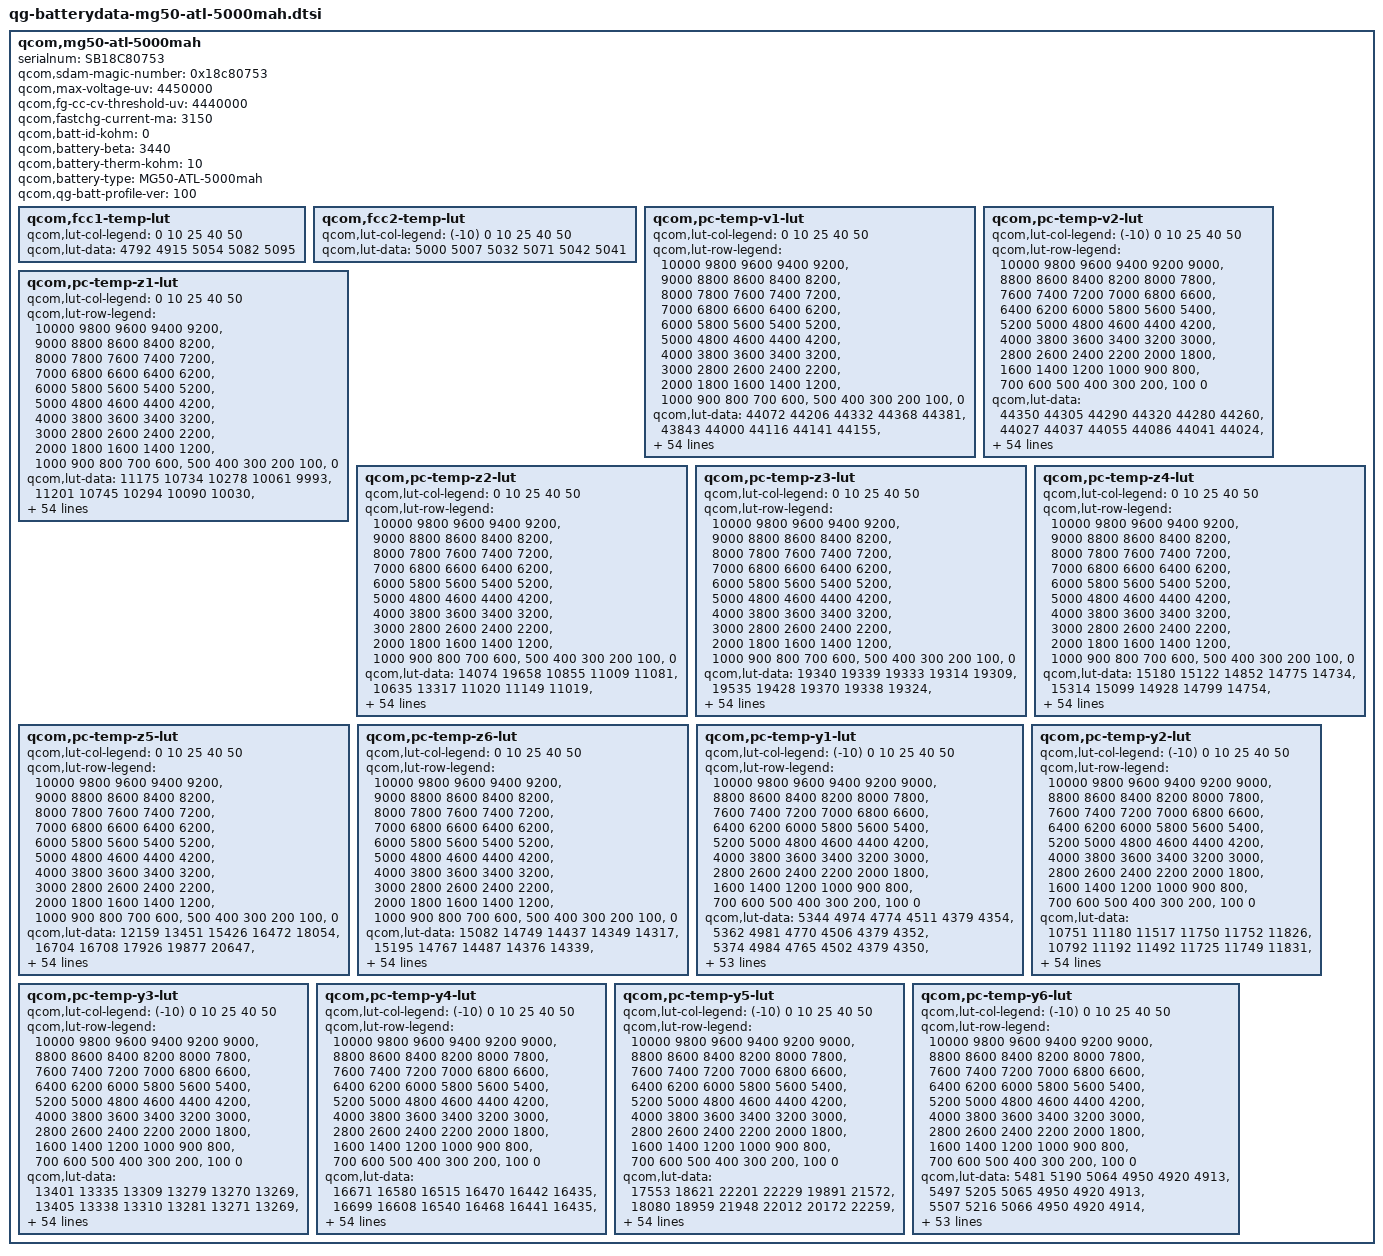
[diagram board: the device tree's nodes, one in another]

qcom,mg50-atl-5000mah {
    /* 4674913_Lenovo_Odessa_5000mAH_PM7150_averaged_MasterSlave_Jun29th2020 */
    serialnum = "SB18C80753";
    qcom,sdam-magic-number = <0x18c80753>;
    qcom,max-voltage-uv = <4450000>;
    qcom,fg-cc-cv-threshold-uv = <4440000>;
    qcom,fastchg-current-ma = <3150>;
    qcom,batt-id-kohm = <0>;
    qcom,battery-beta = <3440>;
    qcom,battery-therm-kohm = <10>;
    qcom,battery-type = "MG50-ATL-5000mah";
    qcom,qg-batt-profile-ver = <100>;

	qcom,fcc1-temp-lut {
		qcom,lut-col-legend = <0 10 25 40 50>;
		qcom,lut-data = <4792 4915 5054 5082 5095>;
	};

	qcom,fcc2-temp-lut {
		qcom,lut-col-legend = <(-10) 0 10 25 40 50>;
		qcom,lut-data = <5000 5007 5032 5071 5042 5041>;
	};

	qcom,pc-temp-v1-lut {
		qcom,lut-col-legend = <0 10 25 40 50>;
		qcom,lut-row-legend = <10000 9800 9600 9400 9200>,
			<9000 8800 8600 8400 8200>,
			<8000 7800 7600 7400 7200>,
			<7000 6800 6600 6400 6200>,
			<6000 5800 5600 5400 5200>,
			<5000 4800 4600 4400 4200>,
			<4000 3800 3600 3400 3200>,
			<3000 2800 2600 2400 2200>,
			<2000 1800 1600 1400 1200>,
			<1000 900 800 700 600>,
			<500 400 300 200 100>,
			<0>;
		qcom,lut-data = <44072 44206 44332 44368 44381>,
			<43843 44000 44116 44141 44155>,
			<43634 43792 43920 43941 43952>,
			<43423 43587 43721 43746 43757>,
			<43199 43375 43511 43540 43554>,
			<42969 43151 43294 43328 43345>,
			<42738 42916 43067 43106 43127>,
			<42504 42679 42830 42875 42897>,
			<42273 42442 42590 42638 42661>,
			<42047 42205 42348 42398 42422>,
			<41824 41973 42105 42156 42181>,
			<41606 41746 41868 41918 41943>,
			<41391 41523 41636 41684 41707>,
			<41184 41305 41408 41454 41476>,
			<40986 41092 41186 41230 41251>,
			<40799 40889 40969 41011 41033>,
			<40612 40694 40761 40800 40821>,
			<40421 40504 40560 40596 40616>,
			<40228 40327 40368 40399 40417>,
			<40029 40147 40192 40217 40232>,
			<39813 39921 40013 40039 40054>,
			<39597 39625 39783 39822 39840>,
			<39399 39374 39504 39553 39571>,
			<39213 39221 39279 39316 39328>,
			<39069 39102 39123 39143 39157>,
			<38967 38986 38992 38997 39013>,
			<38884 38874 38867 38868 38882>,
			<38800 38770 38752 38755 38763>,
			<38717 38675 38648 38650 38653>,
			<38640 38586 38551 38549 38551>,
			<38570 38507 38464 38456 38457>,
			<38504 38434 38385 38370 38368>,
			<38445 38369 38313 38292 38286>,
			<38390 38311 38249 38219 38207>,
			<38340 38260 38195 38153 38133>,
			<38297 38212 38143 38089 38060>,
			<38261 38172 38092 38023 37981>,
			<38214 38128 38042 37956 37895>,
			<38134 38056 37973 37876 37803>,
			<38027 37949 37871 37775 37701>,
			<37909 37830 37753 37660 37589>,
			<37771 37697 37625 37531 37457>,
			<37615 37548 37482 37389 37309>,
			<37436 37369 37312 37227 37146>,
			<37300 37221 37171 37096 37025>,
			<37227 37131 37088 37026 36959>,
			<37189 37108 37063 37004 36939>,
			<37156 37084 37048 36986 36923>,
			<37123 37057 37021 36959 36894>,
			<37046 36976 36900 36820 36726>,
			<36751 36648 36548 36469 36367>,
			<36283 36178 36066 35992 35890>,
			<35689 35573 35442 35379 35273>,
			<34884 34743 34592 34543 34431>,
			<33624 33444 33248 33241 33115>,
			<30000 30000 30000 30000 30000>;
	};

	qcom,pc-temp-v2-lut {
		qcom,lut-col-legend = <(-10) 0 10 25 40 50>;
		qcom,lut-row-legend = <10000 9800 9600 9400 9200 9000>,
			<8800 8600 8400 8200 8000 7800>,
			<7600 7400 7200 7000 6800 6600>,
			<6400 6200 6000 5800 5600 5400>,
			<5200 5000 4800 4600 4400 4200>,
			<4000 3800 3600 3400 3200 3000>,
			<2800 2600 2400 2200 2000 1800>,
			<1600 1400 1200 1000 900 800>,
			<700 600 500 400 300 200>,
			<100 0>;
		qcom,lut-data = <44350 44305 44290 44320 44280 44260>,
			<44027 44037 44055 44086 44041 44024>,
			<43729 43784 43828 43859 43810 43795>,
			<43462 43552 43612 43643 43591 43578>,
			<43225 43339 43405 43436 43382 43370>,
			<42991 43124 43193 43223 43168 43158>,
			<42748 42894 42965 42992 42939 42930>,
			<42505 42657 42729 42754 42702 42696>,
			<42261 42420 42492 42514 42465 42461>,
			<42016 42178 42251 42270 42224 42222>,
			<41770 41939 42012 42029 41986 41985>,
			<41512 41702 41776 41790 41750 41749>,
			<41263 41470 41543 41555 41518 41516>,
			<41075 41247 41315 41323 41289 41288>,
			<40937 41030 41091 41096 41066 41065>,
			<40776 40821 40873 40877 40849 40849>,
			<40519 40627 40663 40667 40641 40639>,
			<40209 40432 40458 40462 40439 40436>,
			<39931 40208 40259 40267 40248 40245>,
			<39676 39952 40065 40078 40068 40065>,
			<39435 39695 39851 39867 39867 39866>,
			<39205 39441 39581 39613 39620 39622>,
			<38990 39199 39309 39365 39370 39375>,
			<38799 38999 39101 39156 39164 39172>,
			<38621 38828 38928 38969 38982 38993>,
			<38470 38676 38775 38813 38828 38840>,
			<38348 38541 38638 38683 38700 38711>,
			<38248 38418 38515 38567 38587 38597>,
			<38172 38299 38402 38458 38480 38488>,
			<38112 38183 38298 38356 38380 38387>,
			<38057 38087 38203 38264 38289 38294>,
			<38004 38013 38115 38180 38207 38210>,
			<37953 37953 38035 38101 38129 38131>,
			<37900 37903 37960 38026 38054 38050>,
			<37846 37863 37889 37952 37980 37970>,
			<37789 37823 37825 37871 37892 37873>,
			<37727 37783 37771 37783 37775 37740>,
			<37659 37741 37716 37692 37656 37606>,
			<37580 37682 37644 37599 37555 37500>,
			<37486 37603 37558 37500 37460 37405>,
			<37380 37499 37458 37400 37358 37302>,
			<37259 37350 37336 37295 37248 37189>,
			<37123 37180 37198 37168 37120 37059>,
			<36976 37012 37040 37026 36972 36909>,
			<36848 36865 36920 36914 36879 36826>,
			<36758 36785 36858 36888 36853 36799>,
			<36717 36755 36833 36867 36835 36782>,
			<36673 36718 36803 36841 36817 36766>,
			<36613 36662 36747 36791 36775 36703>,
			<36496 36550 36599 36596 36581 36454>,
			<36235 36276 36230 36161 36171 36023>,
			<35798 35804 35689 35599 35639 35473>,
			<35199 35168 34986 34865 34949 34756>,
			<34382 34327 33999 33813 33986 33767>,
			<33143 33052 32505 32418 32692 32474>,
			<30382 30452 30248 29025 29492 29251>;
	};

	qcom,pc-temp-z1-lut {
		qcom,lut-col-legend = <0 10 25 40 50>;
		qcom,lut-row-legend = <10000 9800 9600 9400 9200>,
			<9000 8800 8600 8400 8200>,
			<8000 7800 7600 7400 7200>,
			<7000 6800 6600 6400 6200>,
			<6000 5800 5600 5400 5200>,
			<5000 4800 4600 4400 4200>,
			<4000 3800 3600 3400 3200>,
			<3000 2800 2600 2400 2200>,
			<2000 1800 1600 1400 1200>,
			<1000 900 800 700 600>,
			<500 400 300 200 100>,
			<0>;
		qcom,lut-data = <11175 10734 10278 10061 9993>,
			<11201 10745 10294 10090 10030>,
			<11218 10745 10295 10092 10036>,
			<11226 10736 10295 10093 10038>,
			<11211 10724 10289 10092 10041>,
			<11175 10714 10279 10091 10043>,
			<11149 10701 10273 10090 10044>,
			<11130 10691 10269 10090 10043>,
			<11118 10677 10265 10089 10042>,
			<11116 10664 10261 10088 10042>,
			<11108 10661 10258 10086 10042>,
			<11098 10661 10254 10085 10042>,
			<11079 10660 10251 10084 10042>,
			<11057 10654 10249 10083 10042>,
			<11049 10648 10249 10083 10042>,
			<11042 10648 10248 10084 10043>,
			<11039 10651 10248 10084 10044>,
			<11040 10652 10249 10085 10044>,
			<11043 10645 10249 10086 10045>,
			<11046 10634 10250 10087 10046>,
			<11043 10634 10252 10088 10047>,
			<11037 10640 10254 10089 10049>,
			<11035 10644 10256 10090 10050>,
			<11035 10644 10258 10091 10051>,
			<11037 10645 10261 10093 10052>,
			<11040 10645 10264 10095 10054>,
			<11042 10648 10268 10098 10056>,
			<11042 10650 10272 10100 10058>,
			<11039 10652 10276 10103 10059>,
			<11036 10656 10281 10105 10061>,
			<11039 10659 10286 10108 10063>,
			<11050 10664 10289 10111 10065>,
			<11055 10668 10291 10114 10067>,
			<11055 10671 10294 10117 10069>,
			<11057 10675 10301 10120 10072>,
			<11062 10678 10309 10123 10074>,
			<11075 10683 10313 10126 10076>,
			<11084 10689 10318 10130 10078>,
			<11083 10697 10322 10133 10080>,
			<11080 10710 10329 10135 10083>,
			<11086 10717 10335 10137 10084>,
			<11114 10715 10341 10140 10086>,
			<11134 10714 10346 10142 10088>,
			<11144 10731 10349 10144 10089>,
			<11148 10738 10354 10147 10090>,
			<11123 10751 10362 10148 10092>,
			<11135 10746 10359 10149 10091>,
			<11128 10728 10362 10149 10092>,
			<11129 10744 10362 10151 10093>,
			<11150 10758 10375 10155 10095>,
			<11159 10760 10379 10158 10098>,
			<11166 10767 10389 10163 10101>,
			<11186 10773 10393 10168 10107>,
			<11205 10788 10404 10176 10115>,
			<11205 10788 10404 10176 10115>,
			<11205 10788 10404 10176 10115>;
	};

	qcom,pc-temp-z2-lut {
		qcom,lut-col-legend = <0 10 25 40 50>;
		qcom,lut-row-legend = <10000 9800 9600 9400 9200>,
			<9000 8800 8600 8400 8200>,
			<8000 7800 7600 7400 7200>,
			<7000 6800 6600 6400 6200>,
			<6000 5800 5600 5400 5200>,
			<5000 4800 4600 4400 4200>,
			<4000 3800 3600 3400 3200>,
			<3000 2800 2600 2400 2200>,
			<2000 1800 1600 1400 1200>,
			<1000 900 800 700 600>,
			<500 400 300 200 100>,
			<0>;
		qcom,lut-data = <14074 19658 10855 11009 11081>,
			<10635 13317 11020 11149 11019>,
			<10632 10817 11021 11138 11021>,
			<10629 10785 11019 11116 11040>,
			<10608 10755 10969 11070 11019>,
			<10569 10722 10884 10985 10952>,
			<10538 10687 10854 10932 10926>,
			<10514 10659 10844 10900 10910>,
			<10497 10634 10838 10878 10887>,
			<10487 10618 10837 10873 10888>,
			<10480 10626 10841 10874 10894>,
			<10478 10658 10848 10880 10901>,
			<10488 10683 10862 10889 10913>,
			<10508 10694 10871 10896 10927>,
			<10531 10702 10874 10891 10938>,
			<10564 10712 10877 10878 10953>,
			<10589 10721 10879 10880 10972>,
			<10598 10731 10882 10911 11018>,
			<10603 10742 10887 10941 11062>,
			<10611 10751 10894 10952 11078>,
			<10629 10752 10907 10965 11089>,
			<10645 10746 10934 11028 11158>,
			<10638 10742 10988 11277 11522>,
			<10608 10743 11030 11437 11782>,
			<10590 10744 11064 11433 11614>,
			<10589 10749 11086 11405 11290>,
			<10589 10776 11076 11321 11100>,
			<10590 10796 11039 11086 10969>,
			<10597 10786 11003 10946 10893>,
			<10607 10766 10952 10923 10859>,
			<10620 10761 10912 10909 10839>,
			<10635 10774 10919 10895 10848>,
			<10650 10790 10952 10878 10898>,
			<10665 10803 10985 10873 10961>,
			<10678 10816 11022 10932 11056>,
			<10686 10822 11053 11018 11158>,
			<10691 10823 11066 11075 11230>,
			<10698 10825 11075 11125 11291>,
			<10712 10838 11094 11190 11308>,
			<10727 10871 11159 11305 11286>,
			<10730 10885 11207 11388 11264>,
			<10724 10868 11190 11378 11268>,
			<10730 10857 11163 11356 11277>,
			<10796 10887 11162 11313 11273>,
			<10719 11073 11202 11245 11250>,
			<10490 11170 11242 11259 11228>,
			<10667 11143 11235 11249 11228>,
			<10873 11129 11163 11257 11311>,
			<10913 11140 11141 11309 11493>,
			<11029 11204 11243 11211 11218>,
			<10707 11289 11173 10995 10981>,
			<10594 11388 11100 10933 10928>,
			<10534 11627 11039 10873 10865>,
			<10232 11587 10962 10792 10789>,
			<10232 11587 10962 10792 10789>,
			<10232 11587 10962 10792 10789>;
	};

	qcom,pc-temp-z3-lut {
		qcom,lut-col-legend = <0 10 25 40 50>;
		qcom,lut-row-legend = <10000 9800 9600 9400 9200>,
			<9000 8800 8600 8400 8200>,
			<8000 7800 7600 7400 7200>,
			<7000 6800 6600 6400 6200>,
			<6000 5800 5600 5400 5200>,
			<5000 4800 4600 4400 4200>,
			<4000 3800 3600 3400 3200>,
			<3000 2800 2600 2400 2200>,
			<2000 1800 1600 1400 1200>,
			<1000 900 800 700 600>,
			<500 400 300 200 100>,
			<0>;
		qcom,lut-data = <19340 19339 19333 19314 19309>,
			<19535 19428 19370 19338 19324>,
			<19573 19471 19385 19347 19332>,
			<19590 19484 19394 19353 19335>,
			<19602 19492 19400 19358 19337>,
			<19609 19496 19403 19362 19340>,
			<19611 19498 19403 19363 19341>,
			<19612 19499 19397 19357 19338>,
			<19612 19497 19392 19350 19334>,
			<19611 19494 19389 19347 19333>,
			<19608 19489 19387 19346 19332>,
			<19604 19480 19383 19344 19331>,
			<19600 19474 19378 19341 19330>,
			<19595 19470 19374 19338 19329>,
			<19589 19468 19372 19335 19326>,
			<19582 19466 19370 19332 19323>,
			<19577 19464 19368 19330 19320>,
			<19573 19462 19366 19328 19318>,
			<19569 19458 19364 19327 19315>,
			<19568 19453 19362 19324 19313>,
			<19580 19455 19361 19322 19311>,
			<19594 19469 19363 19323 19311>,
			<19594 19478 19370 19329 19319>,
			<19588 19469 19373 19339 19329>,
			<19583 19452 19368 19354 19341>,
			<19581 19450 19362 19369 19351>,
			<19578 19464 19368 19369 19353>,
			<19577 19476 19388 19363 19348>,
			<19575 19476 19396 19356 19342>,
			<19574 19474 19393 19351 19336>,
			<19572 19472 19389 19346 19330>,
			<19568 19468 19385 19341 19325>,
			<19566 19465 19380 19336 19321>,
			<19564 19462 19376 19332 19317>,
			<19563 19460 19372 19327 19312>,
			<19561 19459 19370 19324 19308>,
			<19559 19457 19368 19324 19309>,
			<19556 19456 19366 19325 19311>,
			<19552 19453 19366 19327 19314>,
			<19545 19448 19365 19330 19317>,
			<19540 19444 19365 19332 19319>,
			<19536 19441 19363 19332 19319>,
			<19529 19437 19359 19331 19319>,
			<19514 19431 19358 19333 19323>,
			<19387 19406 19350 19330 19321>,
			<19262 19393 19337 19313 19306>,
			<19261 19388 19338 19311 19304>,
			<19260 19388 19332 19308 19300>,
			<19260 19390 19331 19306 19294>,
			<19260 19382 19332 19317 19309>,
			<19261 19375 19339 19325 19314>,
			<19261 19349 19345 19327 19314>,
			<19261 19311 19348 19327 19315>,
			<19263 19304 19346 19329 19318>,
			<19263 19304 19346 19329 19318>,
			<19263 19304 19346 19329 19318>;
	};

	qcom,pc-temp-z4-lut {
		qcom,lut-col-legend = <0 10 25 40 50>;
		qcom,lut-row-legend = <10000 9800 9600 9400 9200>,
			<9000 8800 8600 8400 8200>,
			<8000 7800 7600 7400 7200>,
			<7000 6800 6600 6400 6200>,
			<6000 5800 5600 5400 5200>,
			<5000 4800 4600 4400 4200>,
			<4000 3800 3600 3400 3200>,
			<3000 2800 2600 2400 2200>,
			<2000 1800 1600 1400 1200>,
			<1000 900 800 700 600>,
			<500 400 300 200 100>,
			<0>;
		qcom,lut-data = <15180 15122 14852 14775 14734>,
			<15314 15099 14928 14799 14754>,
			<15233 15061 14880 14778 14744>,
			<15137 14995 14827 14747 14721>,
			<15062 14923 14792 14724 14704>,
			<14991 14872 14763 14703 14686>,
			<14935 14829 14739 14690 14675>,
			<14890 14795 14718 14683 14670>,
			<14853 14767 14703 14677 14666>,
			<14823 14745 14696 14672 14662>,
			<14799 14731 14690 14668 14658>,
			<14779 14721 14686 14664 14655>,
			<14760 14715 14683 14660 14651>,
			<14746 14712 14680 14657 14647>,
			<14738 14710 14675 14653 14644>,
			<14733 14708 14671 14650 14642>,
			<14731 14706 14669 14646 14639>,
			<14736 14705 14667 14642 14635>,
			<14746 14706 14666 14639 14632>,
			<14755 14708 14665 14638 14630>,
			<14761 14717 14664 14638 14628>,
			<14768 14758 14678 14645 14633>,
			<14782 14790 14726 14684 14668>,
			<14806 14797 14750 14708 14695>,
			<14817 14800 14754 14695 14683>,
			<14808 14798 14755 14675 14663>,
			<14791 14771 14745 14667 14655>,
			<14780 14745 14713 14664 14651>,
			<14772 14735 14694 14661 14649>,
			<14766 14729 14689 14658 14647>,
			<14763 14727 14686 14654 14645>,
			<14762 14727 14685 14652 14642>,
			<14761 14727 14684 14651 14639>,
			<14760 14728 14684 14650 14638>,
			<14759 14728 14684 14650 14637>,
			<14757 14728 14685 14651 14637>,
			<14754 14725 14686 14652 14640>,
			<14749 14722 14687 14656 14646>,
			<14743 14719 14688 14657 14648>,
			<14737 14717 14689 14658 14647>,
			<14728 14713 14689 14658 14645>,
			<14714 14701 14684 14657 14645>,
			<14699 14687 14674 14653 14645>,
			<14684 14676 14667 14649 14643>,
			<14742 14654 14655 14641 14635>,
			<14847 14640 14639 14634 14625>,
			<14845 14637 14630 14628 14619>,
			<14843 14631 14626 14618 14612>,
			<14841 14625 14623 14613 14610>,
			<14837 14634 14630 14617 14615>,
			<14839 14648 14631 14620 14619>,
			<14841 14676 14627 14620 14621>,
			<14841 14722 14625 14621 14622>,
			<14843 14731 14628 14621 14621>,
			<14843 14731 14628 14621 14621>,
			<14843 14731 14628 14621 14621>;
	};

	qcom,pc-temp-z5-lut {
		qcom,lut-col-legend = <0 10 25 40 50>;
		qcom,lut-row-legend = <10000 9800 9600 9400 9200>,
			<9000 8800 8600 8400 8200>,
			<8000 7800 7600 7400 7200>,
			<7000 6800 6600 6400 6200>,
			<6000 5800 5600 5400 5200>,
			<5000 4800 4600 4400 4200>,
			<4000 3800 3600 3400 3200>,
			<3000 2800 2600 2400 2200>,
			<2000 1800 1600 1400 1200>,
			<1000 900 800 700 600>,
			<500 400 300 200 100>,
			<0>;
		qcom,lut-data = <12159 13451 15426 16472 18054>,
			<16704 16708 17926 19877 20647>,
			<18288 18834 19164 21162 22388>,
			<19464 20026 20318 22189 23392>,
			<20633 21031 21173 23584 24429>,
			<21662 22253 21911 25185 26014>,
			<22806 23555 22543 25730 27034>,
			<24112 24924 23151 25444 27245>,
			<25479 26535 23750 25130 27437>,
			<26823 28054 24485 25393 28021>,
			<28190 29034 25142 26150 29113>,
			<29763 29744 25208 26669 30305>,
			<31900 30365 24952 26911 31837>,
			<33996 30897 24794 27029 32994>,
			<35287 31431 25273 27141 32951>,
			<36388 32303 26159 27424 32530>,
			<37218 33703 26865 28076 32510>,
			<37375 34448 27505 29688 33995>,
			<37043 33014 28126 30889 35702>,
			<37544 30854 28771 31077 36676>,
			<43479 31960 29346 31167 37449>,
			<50277 40287 29783 31365 37646>,
			<49926 46119 30173 31716 37259>,
			<44182 39772 30165 31935 36574>,
			<40057 28512 25733 31622 34805>,
			<39373 26002 20717 31048 32551>,
			<38941 29687 21789 30679 32274>,
			<39236 34208 26726 30064 32930>,
			<41569 37618 30752 29789 33289>,
			<44252 40789 33311 30663 32632>,
			<46116 43137 35486 31937 31750>,
			<47819 44977 37709 32715 31897>,
			<49046 46259 39916 33596 32931>,
			<50010 46972 41126 34197 33630>,
			<50622 47499 41783 34651 33907>,
			<50576 47624 42113 35164 34186>,
			<50167 47015 41657 35791 34853>,
			<49735 45973 40346 36535 36255>,
			<49221 44592 38995 37073 37580>,
			<48656 42661 37439 37419 38786>,
			<48402 41595 36148 37718 39949>,
			<48274 41249 35289 38165 40887>,
			<48208 41102 34714 38513 41943>,
			<47804 40909 34596 39387 46586>,
			<31426 42089 33066 37216 43900>,
			<12145 43348 32153 26343 27915>,
			<12074 37719 37151 27977 30700>,
			<12029 38889 33456 33798 35395>,
			<12012 42098 33477 37122 32905>,
			<12027 32659 28730 41389 45599>,
			<12103 25844 28701 39604 40548>,
			<12025 20655 30953 38536 36123>,
			<11935 14143 32422 34663 33089>,
			<11885 13609 29058 32801 31621>,
			<11885 13609 29058 32801 31621>,
			<11885 13609 29058 32801 31621>;
	};

	qcom,pc-temp-z6-lut {
		qcom,lut-col-legend = <0 10 25 40 50>;
		qcom,lut-row-legend = <10000 9800 9600 9400 9200>,
			<9000 8800 8600 8400 8200>,
			<8000 7800 7600 7400 7200>,
			<7000 6800 6600 6400 6200>,
			<6000 5800 5600 5400 5200>,
			<5000 4800 4600 4400 4200>,
			<4000 3800 3600 3400 3200>,
			<3000 2800 2600 2400 2200>,
			<2000 1800 1600 1400 1200>,
			<1000 900 800 700 600>,
			<500 400 300 200 100>,
			<0>;
		qcom,lut-data = <15082 14749 14437 14349 14317>,
			<15195 14767 14487 14376 14339>,
			<15147 14769 14474 14371 14338>,
			<15087 14737 14457 14362 14333>,
			<15034 14693 14444 14356 14328>,
			<14981 14662 14431 14350 14323>,
			<14935 14635 14419 14344 14318>,
			<14896 14611 14406 14337 14314>,
			<14862 14591 14396 14331 14311>,
			<14834 14573 14390 14327 14308>,
			<14809 14559 14386 14324 14306>,
			<14788 14548 14381 14321 14304>,
			<14769 14540 14377 14318 14301>,
			<14753 14536 14373 14315 14299>,
			<14742 14532 14369 14311 14296>,
			<14733 14529 14366 14308 14293>,
			<14729 14526 14364 14306 14290>,
			<14729 14524 14362 14303 14287>,
			<14729 14521 14361 14301 14285>,
			<14731 14519 14360 14299 14283>,
			<14738 14523 14359 14298 14281>,
			<14748 14549 14366 14302 14283>,
			<14755 14568 14392 14323 14305>,
			<14763 14566 14403 14338 14321>,
			<14766 14561 14403 14339 14320>,
			<14761 14558 14402 14340 14319>,
			<14754 14555 14401 14339 14317>,
			<14750 14552 14398 14334 14314>,
			<14747 14549 14395 14330 14310>,
			<14745 14546 14392 14326 14306>,
			<14743 14545 14390 14322 14302>,
			<14742 14544 14387 14319 14299>,
			<14742 14543 14385 14316 14295>,
			<14742 14543 14384 14313 14292>,
			<14743 14544 14383 14311 14290>,
			<14744 14545 14383 14310 14288>,
			<14745 14546 14383 14311 14289>,
			<14746 14546 14384 14313 14293>,
			<14747 14547 14385 14315 14296>,
			<14748 14547 14387 14318 14297>,
			<14748 14547 14388 14319 14297>,
			<14748 14544 14385 14319 14298>,
			<14747 14541 14381 14317 14298>,
			<14743 14538 14379 14316 14299>,
			<14715 14524 14371 14312 14296>,
			<14703 14514 14359 14301 14284>,
			<14703 14511 14356 14297 14280>,
			<14703 14510 14352 14291 14274>,
			<14705 14511 14351 14288 14270>,
			<14710 14515 14356 14296 14281>,
			<14715 14521 14362 14302 14286>,
			<14721 14524 14364 14304 14288>,
			<14729 14528 14367 14307 14291>,
			<14740 14536 14371 14310 14294>,
			<14740 14536 14371 14310 14294>,
			<14740 14536 14371 14310 14294>;
	};

	qcom,pc-temp-y1-lut {
		qcom,lut-col-legend = <(-10) 0 10 25 40 50>;
		qcom,lut-row-legend = <10000 9800 9600 9400 9200 9000>,
			<8800 8600 8400 8200 8000 7800>,
			<7600 7400 7200 7000 6800 6600>,
			<6400 6200 6000 5800 5600 5400>,
			<5200 5000 4800 4600 4400 4200>,
			<4000 3800 3600 3400 3200 3000>,
			<2800 2600 2400 2200 2000 1800>,
			<1600 1400 1200 1000 900 800>,
			<700 600 500 400 300 200>,
			<100 0>;
		qcom,lut-data = <5344 4974 4774 4511 4379 4354>,
			<5362 4981 4770 4506 4379 4352>,
			<5374 4984 4765 4502 4379 4350>,
			<5381 4986 4760 4498 4378 4349>,
			<5385 4986 4755 4494 4377 4347>,
			<5385 4986 4750 4490 4376 4346>,
			<5381 4984 4745 4487 4375 4346>,
			<5373 4981 4741 4484 4374 4346>,
			<5372 4981 4739 4482 4373 4345>,
			<5375 4983 4739 4480 4372 4344>,
			<5378 4984 4738 4478 4372 4344>,
			<5380 4983 4735 4476 4371 4343>,
			<5382 4981 4730 4474 4371 4343>,
			<5383 4979 4727 4473 4371 4343>,
			<5385 4977 4725 4472 4370 4343>,
			<5387 4976 4723 4472 4369 4343>,
			<5388 4978 4720 4471 4370 4343>,
			<5388 4981 4717 4471 4371 4344>,
			<5389 4983 4717 4471 4371 4344>,
			<5398 4984 4718 4472 4371 4344>,
			<5406 4986 4720 4473 4371 4345>,
			<5402 4988 4721 4474 4372 4346>,
			<5394 4990 4722 4475 4373 4347>,
			<5391 4991 4723 4477 4374 4347>,
			<5395 4990 4724 4479 4375 4348>,
			<5399 4990 4725 4482 4375 4348>,
			<5395 4992 4725 4484 4377 4349>,
			<5388 4994 4725 4486 4378 4350>,
			<5387 4993 4726 4488 4379 4350>,
			<5394 4988 4730 4491 4380 4352>,
			<5401 4986 4733 4493 4381 4353>,
			<5402 4990 4735 4497 4383 4354>,
			<5403 4996 4737 4500 4385 4355>,
			<5403 4998 4739 4502 4387 4357>,
			<5403 4999 4742 4505 4388 4359>,
			<5403 5000 4744 4507 4390 4360>,
			<5402 5002 4745 4511 4391 4361>,
			<5394 5003 4746 4514 4392 4362>,
			<5391 5004 4749 4516 4393 4363>,
			<5400 5004 4753 4518 4395 4363>,
			<5409 5004 4757 4520 4396 4364>,
			<5409 5005 4762 4522 4397 4365>,
			<5409 5007 4766 4524 4398 4366>,
			<5406 5022 4770 4525 4400 4367>,
			<5405 5022 4777 4531 4401 4368>,
			<5439 5027 4773 4534 4403 4370>,
			<5441 5022 4780 4535 4403 4370>,
			<5451 5021 4786 4539 4403 4370>,
			<5446 5033 4795 4540 4404 4370>,
			<5452 5034 4793 4537 4404 4371>,
			<5474 5030 4793 4540 4405 4373>,
			<5489 5044 4802 4545 4408 4375>,
			<5552 5054 4810 4553 4412 4379>,
			<5636 5089 4816 4561 4417 4384>,
			<5636 5089 4816 4561 4417 4384>,
			<5636 5089 4816 4561 4417 4384>;
	};

	qcom,pc-temp-y2-lut {
		qcom,lut-col-legend = <(-10) 0 10 25 40 50>;
		qcom,lut-row-legend = <10000 9800 9600 9400 9200 9000>,
			<8800 8600 8400 8200 8000 7800>,
			<7600 7400 7200 7000 6800 6600>,
			<6400 6200 6000 5800 5600 5400>,
			<5200 5000 4800 4600 4400 4200>,
			<4000 3800 3600 3400 3200 3000>,
			<2800 2600 2400 2200 2000 1800>,
			<1600 1400 1200 1000 900 800>,
			<700 600 500 400 300 200>,
			<100 0>;
		qcom,lut-data = <10751 11180 11517 11750 11752 11826>,
			<10792 11192 11492 11725 11749 11831>,
			<10839 11197 11464 11693 11724 11820>,
			<10884 11195 11432 11656 11689 11798>,
			<10917 11190 11399 11614 11657 11765>,
			<10930 11183 11365 11571 11639 11726>,
			<10922 11171 11321 11509 11588 11663>,
			<10911 11154 11281 11458 11521 11601>,
			<10907 11134 11271 11452 11504 11589>,
			<10906 11109 11271 11455 11485 11597>,
			<10906 11096 11271 11459 11468 11600>,
			<10926 11098 11261 11459 11458 11584>,
			<10968 11105 11247 11456 11456 11560>,
			<11013 11119 11248 11450 11470 11540>,
			<11071 11160 11263 11442 11510 11519>,
			<11116 11209 11288 11441 11530 11511>,
			<11144 11272 11353 11473 11517 11518>,
			<11164 11329 11443 11528 11502 11531>,
			<11163 11339 11515 11610 11526 11543>,
			<11137 11341 11585 11726 11612 11560>,
			<11118 11341 11611 11761 11674 11587>,
			<11117 11316 11565 11727 11703 11698>,
			<11118 11282 11510 11697 11723 11826>,
			<11085 11287 11512 11707 11734 11871>,
			<10791 11331 11545 11731 11742 11904>,
			<10493 11368 11573 11746 11758 11935>,
			<10150 11381 11588 11759 11807 11968>,
			<9805 11392 11601 11776 11860 11988>,
			<9755 11407 11616 11799 11887 11994>,
			<9746 11434 11631 11829 11908 12021>,
			<9737 11454 11640 11856 11937 12058>,
			<9723 11461 11642 11892 12016 12117>,
			<9710 11464 11643 11918 12095 12171>,
			<9701 11410 11644 11929 12125 12202>,
			<9695 11080 11644 11937 12147 12229>,
			<9689 10822 11639 11931 12144 12233>,
			<9684 10913 11622 11892 12090 12163>,
			<9681 11107 11594 11869 12042 12094>,
			<9678 11128 11555 11881 12038 12095>,
			<9674 11050 11499 11898 12039 12108>,
			<9672 10903 11439 11907 12032 12098>,
			<9671 10387 11374 11921 12002 12003>,
			<9669 9889 11292 11896 11988 11972>,
			<9667 9769 11179 11829 11989 11989>,
			<9666 9728 11069 11778 11891 11925>,
			<9665 9708 11044 11766 11844 11726>,
			<9664 9696 10967 11714 11741 11654>,
			<9663 9688 10924 11702 11627 11688>,
			<9662 9682 10880 11724 11728 11652>,
			<9661 9677 10803 11687 11711 11582>,
			<9659 9672 10679 11651 11577 11571>,
			<9656 9667 10541 11532 11509 11516>,
			<9652 9663 10302 11401 11421 11383>,
			<9651 9657 9834 11305 11262 11127>,
			<9651 9657 9834 11305 11262 11127>,
			<9651 9657 9834 11305 11262 11127>;
	};

	qcom,pc-temp-y3-lut {
		qcom,lut-col-legend = <(-10) 0 10 25 40 50>;
		qcom,lut-row-legend = <10000 9800 9600 9400 9200 9000>,
			<8800 8600 8400 8200 8000 7800>,
			<7600 7400 7200 7000 6800 6600>,
			<6400 6200 6000 5800 5600 5400>,
			<5200 5000 4800 4600 4400 4200>,
			<4000 3800 3600 3400 3200 3000>,
			<2800 2600 2400 2200 2000 1800>,
			<1600 1400 1200 1000 900 800>,
			<700 600 500 400 300 200>,
			<100 0>;
		qcom,lut-data = <13401 13335 13309 13279 13270 13269>,
			<13405 13338 13310 13281 13271 13269>,
			<13409 13342 13311 13282 13271 13269>,
			<13412 13345 13312 13282 13272 13270>,
			<13416 13349 13313 13283 13272 13270>,
			<13419 13351 13314 13283 13272 13270>,
			<13422 13353 13314 13283 13273 13271>,
			<13425 13354 13315 13283 13273 13271>,
			<13425 13355 13315 13283 13273 13271>,
			<13425 13357 13315 13283 13274 13272>,
			<13424 13358 13316 13283 13274 13273>,
			<13419 13359 13317 13284 13274 13273>,
			<13411 13359 13318 13284 13274 13273>,
			<13406 13359 13318 13284 13275 13273>,
			<13403 13358 13318 13284 13275 13273>,
			<13401 13356 13319 13284 13275 13273>,
			<13402 13351 13317 13287 13276 13273>,
			<13403 13345 13315 13290 13278 13273>,
			<13400 13341 13315 13291 13279 13274>,
			<13388 13340 13314 13291 13281 13275>,
			<13377 13337 13314 13291 13282 13276>,
			<13371 13333 13310 13288 13280 13275>,
			<13366 13328 13305 13285 13277 13274>,
			<13361 13325 13303 13283 13275 13272>,
			<13352 13323 13302 13281 13272 13270>,
			<13343 13321 13300 13280 13271 13269>,
			<13330 13320 13299 13280 13271 13269>,
			<13318 13319 13298 13280 13271 13269>,
			<13318 13316 13297 13280 13271 13269>,
			<13329 13312 13297 13279 13271 13269>,
			<13342 13308 13296 13279 13271 13270>,
			<13352 13305 13296 13279 13271 13270>,
			<13362 13303 13296 13280 13271 13270>,
			<13371 13303 13295 13280 13272 13270>,
			<13381 13305 13295 13279 13272 13270>,
			<13394 13307 13295 13279 13272 13270>,
			<13416 13313 13295 13278 13271 13269>,
			<13444 13321 13295 13277 13270 13268>,
			<13475 13327 13295 13276 13270 13268>,
			<13509 13331 13296 13275 13270 13269>,
			<13548 13333 13296 13275 13270 13269>,
			<13591 13333 13299 13277 13271 13270>,
			<13640 13334 13301 13278 13271 13270>,
			<13701 13348 13304 13279 13271 13269>,
			<13773 13368 13309 13276 13270 13270>,
			<13851 13386 13308 13280 13273 13272>,
			<13903 13405 13311 13281 13275 13273>,
			<13981 13429 13316 13283 13277 13274>,
			<14080 13461 13322 13288 13278 13274>,
			<14206 13506 13329 13287 13277 13273>,
			<14392 13559 13332 13285 13275 13272>,
			<14785 13658 13342 13288 13276 13274>,
			<16302 13860 13363 13290 13279 13276>,
			<21170 14403 13417 13296 13281 13279>,
			<21170 14403 13417 13296 13281 13279>,
			<21170 14403 13417 13296 13281 13279>;
	};

	qcom,pc-temp-y4-lut {
		qcom,lut-col-legend = <(-10) 0 10 25 40 50>;
		qcom,lut-row-legend = <10000 9800 9600 9400 9200 9000>,
			<8800 8600 8400 8200 8000 7800>,
			<7600 7400 7200 7000 6800 6600>,
			<6400 6200 6000 5800 5600 5400>,
			<5200 5000 4800 4600 4400 4200>,
			<4000 3800 3600 3400 3200 3000>,
			<2800 2600 2400 2200 2000 1800>,
			<1600 1400 1200 1000 900 800>,
			<700 600 500 400 300 200>,
			<100 0>;
		qcom,lut-data = <16671 16580 16515 16470 16442 16435>,
			<16699 16608 16540 16468 16441 16435>,
			<16755 16648 16560 16466 16440 16434>,
			<16819 16689 16575 16465 16440 16434>,
			<16872 16720 16584 16465 16439 16434>,
			<16894 16733 16587 16464 16439 16433>,
			<16893 16730 16583 16464 16439 16433>,
			<16890 16724 16574 16464 16440 16433>,
			<16888 16716 16568 16465 16440 16433>,
			<16886 16706 16562 16467 16440 16433>,
			<16885 16700 16560 16469 16441 16434>,
			<16892 16702 16561 16471 16443 16435>,
			<16908 16705 16562 16475 16447 16437>,
			<16953 16714 16566 16480 16450 16439>,
			<17081 16740 16575 16487 16454 16442>,
			<17157 16774 16589 16493 16457 16445>,
			<17090 16832 16619 16499 16461 16449>,
			<16963 16891 16656 16506 16465 16453>,
			<16884 16889 16683 16525 16475 16461>,
			<16833 16829 16708 16556 16491 16472>,
			<16786 16759 16716 16565 16498 16477>,
			<16730 16695 16655 16546 16490 16470>,
			<16678 16636 16571 16518 16477 16459>,
			<16644 16601 16536 16492 16463 16450>,
			<16619 16579 16516 16466 16448 16440>,
			<16611 16562 16506 16460 16442 16437>,
			<16629 16550 16501 16460 16443 16437>,
			<16655 16541 16498 16460 16444 16437>,
			<16659 16528 16498 16462 16446 16438>,
			<16655 16512 16498 16466 16450 16441>,
			<16652 16504 16498 16471 16454 16444>,
			<16655 16506 16499 16478 16459 16448>,
			<16660 16511 16499 16485 16465 16454>,
			<16667 16520 16497 16489 16471 16458>,
			<16678 16538 16490 16492 16477 16463>,
			<16688 16555 16487 16491 16477 16464>,
			<16693 16567 16492 16479 16463 16452>,
			<16698 16579 16497 16466 16448 16441>,
			<16701 16590 16498 16456 16445 16440>,
			<16703 16602 16499 16448 16443 16440>,
			<16705 16608 16501 16447 16442 16440>,
			<16703 16609 16509 16450 16441 16441>,
			<16699 16611 16519 16453 16440 16442>,
			<16691 16615 16532 16456 16439 16437>,
			<16694 16615 16539 16448 16429 16424>,
			<16695 16618 16534 16457 16434 16430>,
			<16705 16630 16551 16466 16441 16445>,
			<16727 16650 16573 16481 16469 16495>,
			<16760 16687 16606 16516 16526 16534>,
			<16793 16729 16629 16512 16487 16468>,
			<16811 16743 16618 16477 16445 16443>,
			<16840 16763 16631 16489 16449 16448>,
			<17185 16826 16679 16514 16460 16459>,
			<20022 16983 16770 16577 16496 16517>,
			<20022 16983 16770 16577 16496 16517>,
			<20022 16983 16770 16577 16496 16517>;
	};

	qcom,pc-temp-y5-lut {
		qcom,lut-col-legend = <(-10) 0 10 25 40 50>;
		qcom,lut-row-legend = <10000 9800 9600 9400 9200 9000>,
			<8800 8600 8400 8200 8000 7800>,
			<7600 7400 7200 7000 6800 6600>,
			<6400 6200 6000 5800 5600 5400>,
			<5200 5000 4800 4600 4400 4200>,
			<4000 3800 3600 3400 3200 3000>,
			<2800 2600 2400 2200 2000 1800>,
			<1600 1400 1200 1000 900 800>,
			<700 600 500 400 300 200>,
			<100 0>;
		qcom,lut-data = <17553 18621 22201 22229 19891 21572>,
			<18080 18959 21948 22012 20172 22259>,
			<18584 19327 21512 21525 20291 22663>,
			<19053 19684 21019 20930 20287 22859>,
			<19472 19991 20595 20388 20195 22921>,
			<19830 20205 20368 20055 20053 22922>,
			<20182 20369 20250 19378 19599 22709>,
			<20459 20488 20148 18583 19029 22425>,
			<20417 20485 20059 18284 18850 22486>,
			<19837 20335 19744 17708 18792 22826>,
			<18999 20105 19414 17252 18692 23000>,
			<17438 19585 19028 16956 18129 22063>,
			<15755 18774 18522 16624 17306 20508>,
			<15679 17828 18007 16099 16695 19416>,
			<17061 16512 17421 15346 16137 18362>,
			<18759 15832 16818 15095 15930 17613>,
			<20757 16279 16038 15627 16286 17068>,
			<22552 17251 15400 16235 16782 16714>,
			<22702 18472 15856 16342 16969 16717>,
			<22065 20268 18062 16349 17078 16895>,
			<21625 21346 20147 16665 17332 17259>,
			<21625 21556 21782 19446 19233 19653>,
			<21727 21690 23058 22043 21343 22213>,
			<21640 21919 23602 22357 21545 22313>,
			<19935 22247 23948 22488 21018 21863>,
			<18043 22554 24031 22497 20745 21621>,
			<15209 22852 23437 22328 20367 21594>,
			<12321 23082 22740 22074 19935 21526>,
			<12080 22695 22599 21680 19562 21117>,
			<12372 20694 22584 21224 18880 20277>,
			<12667 18692 22597 21159 18625 19860>,
			<12857 17129 23205 21440 18632 19738>,
			<13000 15892 23937 21810 18779 19678>,
			<13074 15737 24143 22201 19374 19888>,
			<13112 16402 24311 22614 20287 20490>,
			<13172 16939 24101 22982 20553 20827>,
			<13477 18286 23323 23481 20293 20785>,
			<13858 20535 22405 23746 20070 20764>,
			<13935 21520 21595 22285 20177 21201>,
			<13905 21961 20737 20141 20557 22159>,
			<13848 22015 20293 20317 21171 23169>,
			<13682 18772 20142 22354 22555 24225>,
			<13472 15235 19888 22922 23409 25564>,
			<13262 14488 19198 22894 23781 27362>,
			<12851 13995 19974 20217 22903 27809>,
			<12895 13893 19500 21167 21965 25417>,
			<12744 14044 18967 19654 22607 24946>,
			<12851 13929 18631 20021 23423 22414>,
			<13071 14056 18505 21924 20455 18361>,
			<13519 14321 18673 21923 20866 20040>,
			<13453 14065 18615 23793 22984 22878>,
			<13296 13823 18360 23902 23454 23288>,
			<12169 13523 17358 23496 24862 24795>,
			<10063 12867 15118 23287 24783 25382>,
			<10063 12867 15118 23287 24783 25382>,
			<10063 12867 15118 23287 24783 25382>;
	};

	qcom,pc-temp-y6-lut {
		qcom,lut-col-legend = <(-10) 0 10 25 40 50>;
		qcom,lut-row-legend = <10000 9800 9600 9400 9200 9000>,
			<8800 8600 8400 8200 8000 7800>,
			<7600 7400 7200 7000 6800 6600>,
			<6400 6200 6000 5800 5600 5400>,
			<5200 5000 4800 4600 4400 4200>,
			<4000 3800 3600 3400 3200 3000>,
			<2800 2600 2400 2200 2000 1800>,
			<1600 1400 1200 1000 900 800>,
			<700 600 500 400 300 200>,
			<100 0>;
		qcom,lut-data = <5481 5190 5064 4950 4920 4913>,
			<5497 5205 5065 4950 4920 4913>,
			<5507 5216 5066 4950 4920 4914>,
			<5513 5222 5066 4949 4920 4914>,
			<5516 5225 5066 4949 4920 4914>,
			<5516 5226 5065 4949 4920 4914>,
			<5513 5223 5061 4948 4920 4914>,
			<5507 5217 5056 4948 4921 4914>,
			<5502 5212 5052 4948 4921 4915>,
			<5498 5206 5049 4948 4921 4915>,
			<5493 5202 5047 4948 4922 4916>,
			<5487 5201 5045 4949 4923 4916>,
			<5483 5199 5045 4950 4924 4917>,
			<5489 5200 5045 4952 4925 4917>,
			<5523 5205 5047 4953 4926 4918>,
			<5544 5211 5050 4955 4927 4919>,
			<5529 5223 5056 4958 4929 4920>,
			<5498 5235 5065 4963 4931 4922>,
			<5475 5234 5072 4969 4935 4925>,
			<5455 5215 5078 4978 4941 4929>,
			<5438 5194 5080 4980 4943 4931>,
			<5422 5173 5060 4973 4939 4928>,
			<5409 5153 5033 4963 4934 4924>,
			<5400 5143 5022 4954 4928 4920>,
			<5391 5137 5015 4945 4922 4915>,
			<5387 5133 5012 4943 4920 4914>,
			<5389 5132 5011 4943 4920 4914>,
			<5394 5131 5010 4943 4920 4914>,
			<5403 5129 5010 4944 4921 4915>,
			<5417 5125 5011 4945 4922 4915>,
			<5434 5123 5012 4947 4923 4917>,
			<5452 5125 5013 4950 4925 4918>,
			<5471 5131 5014 4952 4927 4920>,
			<5493 5138 5014 4954 4929 4922>,
			<5517 5149 5014 4955 4931 4923>,
			<5544 5163 5014 4955 4931 4923>,
			<5574 5180 5016 4951 4927 4919>,
			<5607 5200 5020 4947 4922 4916>,
			<5642 5221 5023 4944 4921 4916>,
			<5678 5243 5026 4941 4921 4916>,
			<5718 5264 5030 4941 4921 4916>,
			<5759 5281 5038 4944 4921 4917>,
			<5805 5300 5049 4947 4922 4917>,
			<5857 5331 5061 4948 4921 4916>,
			<5922 5370 5076 4945 4918 4913>,
			<5999 5409 5077 4951 4922 4916>,
			<6049 5440 5090 4954 4925 4921>,
			<6122 5480 5108 4961 4935 4937>,
			<6216 5532 5130 4974 4952 4948>,
			<6339 5594 5152 4972 4940 4928>,
			<6513 5661 5164 4962 4926 4921>,
			<6866 5770 5202 4968 4929 4923>,
			<8213 5975 5272 4978 4934 4929>,
			<12590 6488 5388 5002 4947 4948>,
			<12590 6488 5388 5002 4947 4948>,
			<12590 6488 5388 5002 4947 4948>;
	};

};
